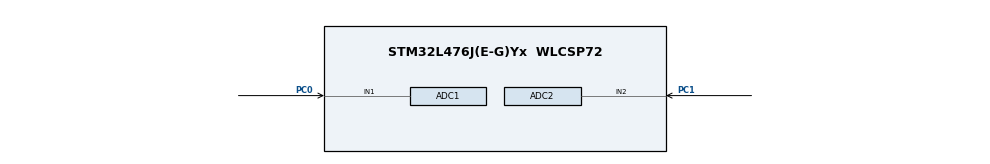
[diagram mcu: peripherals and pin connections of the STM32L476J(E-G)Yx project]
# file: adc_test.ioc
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ADC1.Channel-0\#ChannelRegularConversion=ADC_CHANNEL_1
ADC1.NbrOfConversionFlag=1
ADC1.OffsetNumber-0\#ChannelRegularConversion=ADC_OFFSET_NONE
ADC1.Rank-0\#ChannelRegularConversion=1
ADC1.SamplingTime-0\#ChannelRegularConversion=ADC_SAMPLETIME_2CYCLES_5
ADC1.master=1
ADC2.Channel-1\#ChannelRegularConversion=ADC_CHANNEL_2
ADC2.NbrOfConversionFlag=1
ADC2.OffsetNumber-1\#ChannelRegularConversion=ADC_OFFSET_NONE
ADC2.Rank-1\#ChannelRegularConversion=1
ADC2.SamplingTime-1\#ChannelRegularConversion=ADC_SAMPLETIME_2CYCLES_5
Mcu.Family=STM32L4
Mcu.Name=STM32L476J(E-G)Yx
Mcu.Package=WLCSP72
NVIC.PriorityGroup=NVIC_PRIORITYGROUP_4
PC0.Signal=ADCx_IN1
PC1.Signal=ADCx_IN2
ProjectManager.HeapSize=0x200
ProjectManager.StackSize=0x400
ProjectManager.TargetToolchain=SW4STM32
RCC.ADCFreq_Value=32000000
RCC.HSE_VALUE=8000000
RCC.HSI_VALUE=16000000
RCC.LSE_VALUE=32768
RCC.MSI_VALUE=4000000
RCC.PLLSAI1N=16
RCC.USBFreq_Value=32000000
RCC.VCOOutputFreq_Value=32000000
SH.ADCx_IN1.0=ADC1_IN1,IN1-Single-Ended
SH.ADCx_IN2.0=ADC2_IN2,IN2-Single-Ended
board=custom

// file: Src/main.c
/* USER CODE BEGIN Header */
/**
 ******************************************************************************
 * @file           : main.c
 * @brief          : Main program body
 ******************************************************************************
 * @attention
 *
 * <h2><center>&copy; Copyright (c) 2020 STMicroelectronics.
 * All rights reserved.</center></h2>
 *
 * This software component is licensed by ST under BSD 3-Clause license,
 * the "License"; You may not use this file except in compliance with the
 * License. You may obtain a copy of the License at:
 *                        opensource.org/licenses/BSD-3-Clause
 *
 ******************************************************************************
 */
/* USER CODE END Header */

#include "main.h"

ADC_HandleTypeDef hadc1;
ADC_HandleTypeDef hadc2;

void SystemClock_Config(void);
static void MX_GPIO_Init(void);
static void MX_ADC1_Init(void);
static void MX_ADC2_Init(void);

/* USER CODE BEGIN 0 */
uint32_t val;
/* USER CODE END 0 */

int main(void) {

    /* MCU Configuration--------------------------------------------------------*/

    /* Reset of all peripherals, Initializes the Flash interface and the Systick. */
    HAL_Init();

    /* Configure the system clock */
    SystemClock_Config();

    /* Initialize all configured peripherals */
    MX_GPIO_Init();
    MX_ADC1_Init();
    MX_ADC2_Init();

    /* Infinite loop */
    /* USER CODE BEGIN WHILE */
    while (1) {
        HAL_ADC_Start(&hadc1);
        HAL_ADC_PollForConversion(&hadc1, HAL_MAX_DELAY);
        val = HAL_ADC_GetValue(&hadc1);
        HAL_Delay(10);
        /* USER CODE END WHILE */

    }
}

void SystemClock_Config(void) {
    RCC_OscInitTypeDef RCC_OscInitStruct = { 0 };
    RCC_ClkInitTypeDef RCC_ClkInitStruct = { 0 };
    RCC_PeriphCLKInitTypeDef PeriphClkInit = { 0 };

    /** Initializes the CPU, AHB and APB busses clocks
     */
    RCC_OscInitStruct.OscillatorType = RCC_OSCILLATORTYPE_MSI;
    RCC_OscInitStruct.MSIState = RCC_MSI_ON;
    RCC_OscInitStruct.MSICalibrationValue = 0;
    RCC_OscInitStruct.MSIClockRange = RCC_MSIRANGE_6;
    RCC_OscInitStruct.PLL.PLLState = RCC_PLL_NONE;
    if (HAL_RCC_OscConfig(&RCC_OscInitStruct) != HAL_OK) {
        Error_Handler();
    }
    /** Initializes the CPU, AHB and APB busses clocks
     */
    RCC_ClkInitStruct.ClockType = RCC_CLOCKTYPE_HCLK | RCC_CLOCKTYPE_SYSCLK
            | RCC_CLOCKTYPE_PCLK1 | RCC_CLOCKTYPE_PCLK2;
    RCC_ClkInitStruct.SYSCLKSource = RCC_SYSCLKSOURCE_MSI;
    RCC_ClkInitStruct.AHBCLKDivider = RCC_SYSCLK_DIV1;
    RCC_ClkInitStruct.APB1CLKDivider = RCC_HCLK_DIV1;
    RCC_ClkInitStruct.APB2CLKDivider = RCC_HCLK_DIV1;

    if (HAL_RCC_ClockConfig(&RCC_ClkInitStruct, FLASH_LATENCY_0) != HAL_OK) {
        Error_Handler();
    }
    PeriphClkInit.PeriphClockSelection = RCC_PERIPHCLK_ADC;
    PeriphClkInit.AdcClockSelection = RCC_ADCCLKSOURCE_PLLSAI1;
    PeriphClkInit.PLLSAI1.PLLSAI1Source = RCC_PLLSOURCE_MSI;
    PeriphClkInit.PLLSAI1.PLLSAI1M = 1;
    PeriphClkInit.PLLSAI1.PLLSAI1N = 16;
    PeriphClkInit.PLLSAI1.PLLSAI1P = RCC_PLLP_DIV7;
    PeriphClkInit.PLLSAI1.PLLSAI1Q = RCC_PLLQ_DIV2;
    PeriphClkInit.PLLSAI1.PLLSAI1R = RCC_PLLR_DIV2;
    PeriphClkInit.PLLSAI1.PLLSAI1ClockOut = RCC_PLLSAI1_ADC1CLK;
    if (HAL_RCCEx_PeriphCLKConfig(&PeriphClkInit) != HAL_OK) {
        Error_Handler();
    }
    /** Configure the main internal regulator output voltage
     */
    if (HAL_PWREx_ControlVoltageScaling(PWR_REGULATOR_VOLTAGE_SCALE1)
            != HAL_OK) {
        Error_Handler();
    }
}

static void MX_ADC1_Init(void) {

    ADC_MultiModeTypeDef multimode = { 0 };
    ADC_ChannelConfTypeDef sConfig = { 0 };

    /** Common config
     */
    hadc1.Instance = ADC1;
    hadc1.Init.ClockPrescaler = ADC_CLOCK_ASYNC_DIV1;
    hadc1.Init.Resolution = ADC_RESOLUTION_12B;
    hadc1.Init.DataAlign = ADC_DATAALIGN_RIGHT;
    hadc1.Init.ScanConvMode = ADC_SCAN_DISABLE;
    hadc1.Init.EOCSelection = ADC_EOC_SINGLE_CONV;
    hadc1.Init.LowPowerAutoWait = DISABLE;
    hadc1.Init.ContinuousConvMode = DISABLE;
    hadc1.Init.NbrOfConversion = 1;
    hadc1.Init.DiscontinuousConvMode = DISABLE;
    hadc1.Init.NbrOfDiscConversion = 1;
    hadc1.Init.ExternalTrigConv = ADC_SOFTWARE_START;
    hadc1.Init.ExternalTrigConvEdge = ADC_EXTERNALTRIGCONVEDGE_NONE;
    hadc1.Init.DMAContinuousRequests = DISABLE;
    hadc1.Init.Overrun = ADC_OVR_DATA_PRESERVED;
    hadc1.Init.OversamplingMode = DISABLE;
    if (HAL_ADC_Init(&hadc1) != HAL_OK) {
        Error_Handler();
    }
    /** Configure the ADC multi-mode
     */
    multimode.Mode = ADC_MODE_INDEPENDENT;
    if (HAL_ADCEx_MultiModeConfigChannel(&hadc1, &multimode) != HAL_OK) {
        Error_Handler();
    }
    /** Configure Regular Channel
     */
    sConfig.Channel = ADC_CHANNEL_1;
    sConfig.Rank = ADC_REGULAR_RANK_1;
    sConfig.SamplingTime = ADC_SAMPLETIME_2CYCLES_5;
    sConfig.SingleDiff = ADC_SINGLE_ENDED;
    sConfig.OffsetNumber = ADC_OFFSET_NONE;
    sConfig.Offset = 0;
    if (HAL_ADC_ConfigChannel(&hadc1, &sConfig) != HAL_OK) {
        Error_Handler();
    }

}

static void MX_ADC2_Init(void) {

    ADC_ChannelConfTypeDef sConfig = { 0 };

    /** Common config
     */
    hadc2.Instance = ADC2;
    hadc2.Init.ClockPrescaler = ADC_CLOCK_ASYNC_DIV1;
    hadc2.Init.Resolution = ADC_RESOLUTION_12B;
    hadc2.Init.DataAlign = ADC_DATAALIGN_RIGHT;
    hadc2.Init.ScanConvMode = ADC_SCAN_DISABLE;
    hadc2.Init.EOCSelection = ADC_EOC_SINGLE_CONV;
    hadc2.Init.LowPowerAutoWait = DISABLE;
    hadc2.Init.ContinuousConvMode = DISABLE;
    hadc2.Init.NbrOfConversion = 1;
    hadc2.Init.DiscontinuousConvMode = DISABLE;
    hadc2.Init.NbrOfDiscConversion = 1;
    hadc2.Init.ExternalTrigConv = ADC_SOFTWARE_START;
    hadc2.Init.ExternalTrigConvEdge = ADC_EXTERNALTRIGCONVEDGE_NONE;
    hadc2.Init.DMAContinuousRequests = DISABLE;
    hadc2.Init.Overrun = ADC_OVR_DATA_PRESERVED;
    hadc2.Init.OversamplingMode = DISABLE;
    if (HAL_ADC_Init(&hadc2) != HAL_OK) {
        Error_Handler();
    }
    /** Configure Regular Channel
     */
    sConfig.Channel = ADC_CHANNEL_2;
    sConfig.Rank = ADC_REGULAR_RANK_1;
    sConfig.SamplingTime = ADC_SAMPLETIME_2CYCLES_5;
    sConfig.SingleDiff = ADC_SINGLE_ENDED;
    sConfig.OffsetNumber = ADC_OFFSET_NONE;
    sConfig.Offset = 0;
    if (HAL_ADC_ConfigChannel(&hadc2, &sConfig) != HAL_OK) {
        Error_Handler();
    }

}

static void MX_GPIO_Init(void) {

    /* GPIO Ports Clock Enable */
    __HAL_RCC_GPIOC_CLK_ENABLE()
    ;

}

void Error_Handler(void) {
}

/************************ (C) COPYRIGHT STMicroelectronics *****END OF FILE****/
